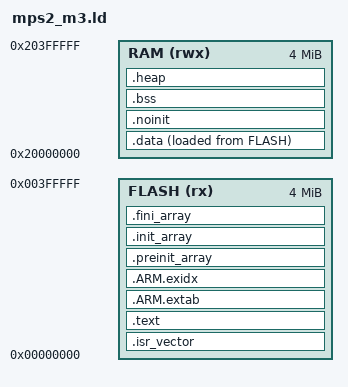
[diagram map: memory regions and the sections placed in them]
/*
 * Based on the linker script from FreeRTOS CORTEX_MPS2_QEMU_IAR_GCC.
 *
 * Copyright (C) 2020 Amazon.com, Inc. or its affiliates.
 * SPDX-License-Identifier: MIT
 */

MEMORY
{
    FLASH (rx) : ORIGIN = 0x00000000, LENGTH = 4M
    RAM  (rwx) : ORIGIN = 0x20000000, LENGTH = 4M
}

ENTRY(Reset_Handler)

_Min_Stack_Size = 0x1000;
_estack = ORIGIN(RAM) + LENGTH(RAM);

SECTIONS
{
    .isr_vector :
    {
        . = ALIGN(4);
        __vector_table = .;
        KEEP(*(.isr_vector))
        . = ALIGN(4);
    } > FLASH

    .text :
    {
        . = ALIGN(4);
        *(.text*)
        *(.rodata*)
        *(.constdata*)
        KEEP(*(.init))
        KEEP(*(.fini))
        . = ALIGN(4);
        _etext = .;
    } > FLASH

    .ARM.extab : { *(.ARM.extab* .gnu.linkonce.armextab.*) } > FLASH
    .ARM.exidx :
    {
        __exidx_start = .;
        *(.ARM.exidx* .gnu.linkonce.armexidx.*)
        __exidx_end = .;
    } > FLASH

    .preinit_array :
    {
        PROVIDE_HIDDEN(__preinit_array_start = .);
        KEEP(*(.preinit_array*))
        PROVIDE_HIDDEN(__preinit_array_end = .);
    } > FLASH

    .init_array :
    {
        PROVIDE_HIDDEN(__init_array_start = .);
        KEEP(*(SORT(.init_array.*)))
        KEEP(*(.init_array*))
        PROVIDE_HIDDEN(__init_array_end = .);
    } > FLASH

    .fini_array :
    {
        PROVIDE_HIDDEN(__fini_array_start = .);
        KEEP(*(SORT(.fini_array.*)))
        KEEP(*(.fini_array*))
        PROVIDE_HIDDEN(__fini_array_end = .);
    } > FLASH

    .data :
    {
        . = ALIGN(8);
        _sdata = .;
        *(.data*)
        *(.vtable)
        . = ALIGN(8);
        _edata = .;
    } > RAM AT > FLASH
    _sidata = LOADADDR(.data);

    /* RAM in this section is intentionally untouched by Reset_Handler. QEMU's
     * SYSRESETREQ keeps it, allowing the demo index to survive a soft reset. */
    .noinit (NOLOAD) :
    {
        . = ALIGN(8);
        __noinit_start__ = .;
        *(.noinit*)
        . = ALIGN(8);
        __noinit_end__ = .;
    } > RAM

    .bss (NOLOAD) :
    {
        . = ALIGN(8);
        _sbss = .;
        *(.bss*)
        *(COMMON)
        . = ALIGN(8);
        _ebss = .;
    } > RAM

    .heap (NOLOAD) :
    {
        . = ALIGN(8);
        PROVIDE(end = .);
        PROVIDE(_end = .);
        _heap_bottom = .;
        . = ALIGN(8);
        _heap_top = .;
    } > RAM

    __StackTop = ORIGIN(RAM) + LENGTH(RAM);
    __StackLimit = __StackTop - _Min_Stack_Size;
    PROVIDE(__stack = __StackTop);

    /DISCARD/ : { *(.note.GNU-stack) }

    ASSERT(__StackLimit >= _heap_top, "RAM overflowed into the main stack")
}
